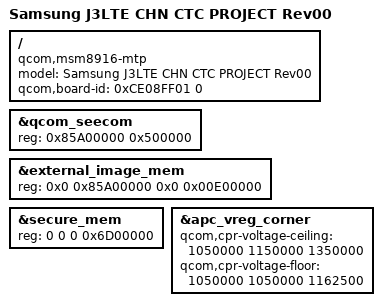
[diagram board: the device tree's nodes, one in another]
/* Copyright (c) 2014, The Linux Foundation. All rights reserved.
*
* This program is free software; you can redistribute it and/or modify
* it under the terms of the GNU General Public License version 2 and
* only version 2 as published by the Free Software Foundation.
*
* This program is distributed in the hope that it will be useful,
* but WITHOUT ANY WARRANTY; without even the implied warranty of
* MERCHANTABILITY or FITNESS FOR A PARTICULAR PURPOSE.  See the
* GNU General Public License for more details.
*/

/dts-v1/;

#include "msm8916-sec-j3lte-chnctc-r00.dtsi"
#include "msm8916-memory.dtsi"

/ {
	model = "Samsung J3LTE CHN CTC PROJECT Rev00";
	compatible = "qcom,msm8916-mtp", "qcom,msm8916", "qcom,mtp";
	/*QCOM BOARD REV TYPE...*/
	/*qcom,board-id = <8 0>;*/
	/*SEC BOARD REV TYPE...*/
	qcom,board-id = <0xCE08FF01 0>;
        /*parm1)[31:24]platform_id [23:16]qc_hw_id [15:8]national code [7:0] operator, param2)SEC hw-rev*/
};

&qcom_seecom {
	reg = <0x85A00000 0x500000>;
};

&external_image_mem {
	reg = <0x0 0x85A00000 0x0 0x00E00000>;
};

&secure_mem {
	reg = <0 0 0 0x6D00000>;
};

/* overwrite s2 cpr voltage for model variant */
&apc_vreg_corner {
	qcom,cpr-voltage-ceiling = <1050000 1150000 1350000>;
	qcom,cpr-voltage-floor = <1050000 1050000 1162500>;
};
